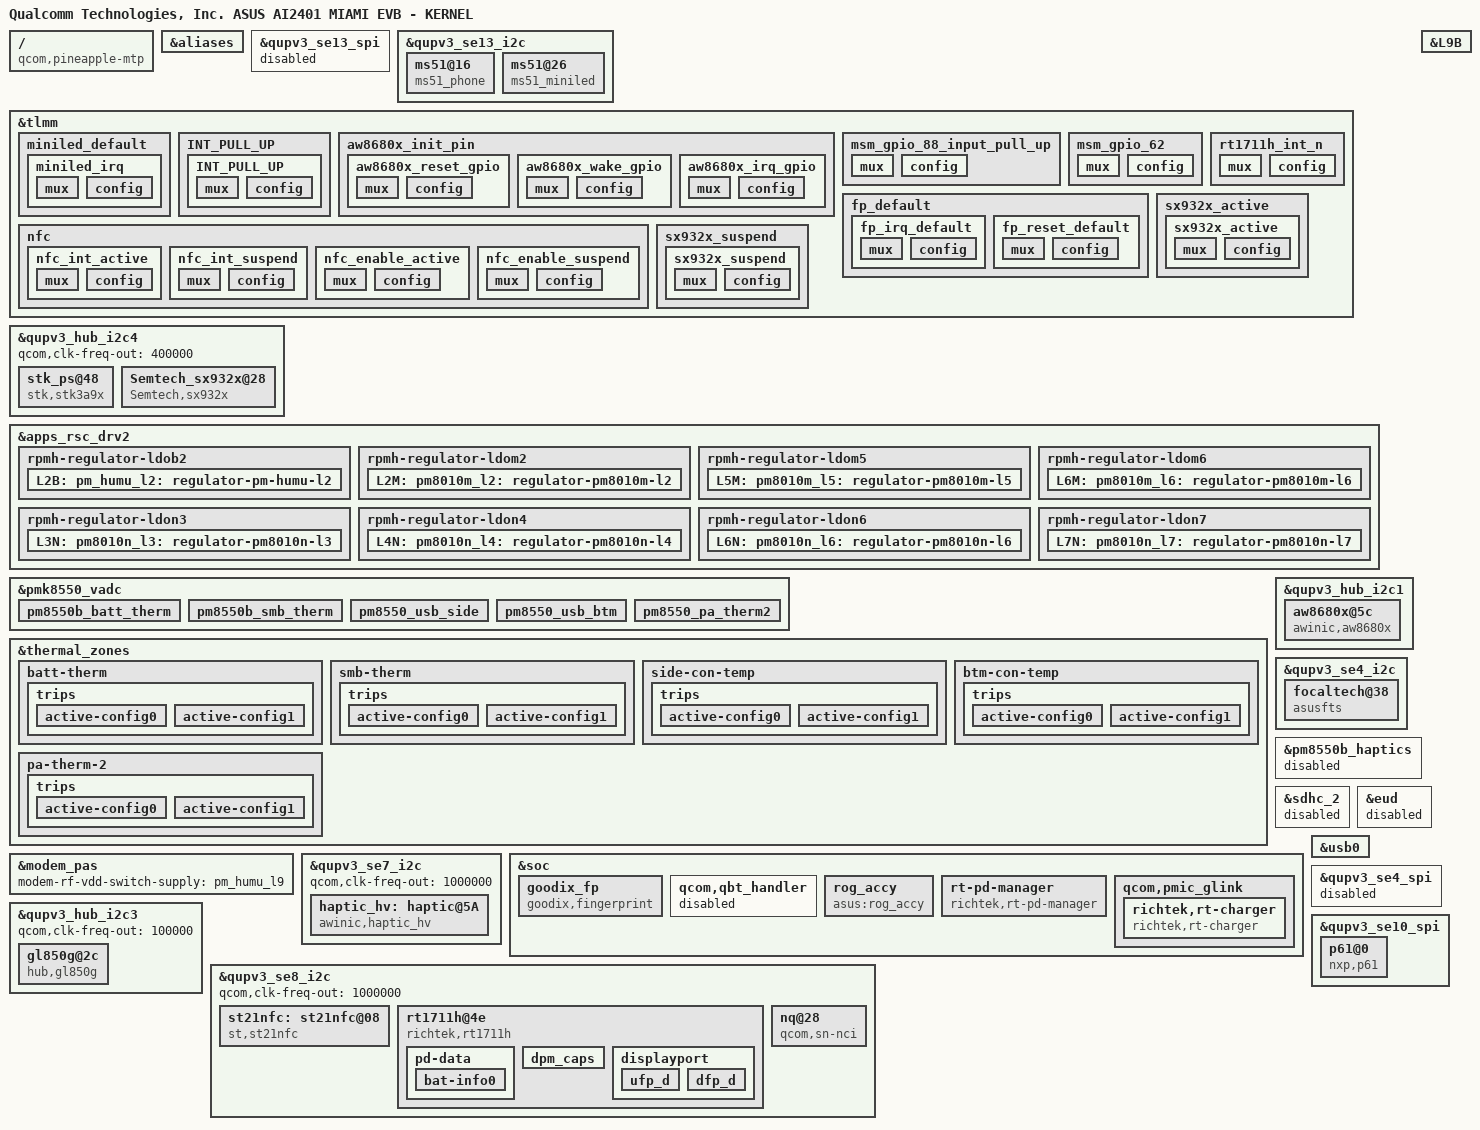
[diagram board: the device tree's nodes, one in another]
/dts-v1/;
/plugin/;

#include "pineapple-mtp.dtsi"

/ {
	model = "Qualcomm Technologies, Inc. ASUS AI2401 MIAMI EVB - KERNEL";
	compatible = "qcom,pineapple-mtp", "qcom,pineapple", "qcom,pineapplep-mtp", "qcom,pineapplep", "qcom,mtp";
	qcom,msm-id = <557 0x10000>, <557 0x20000>, <577 0x10000>, <577 0x20000>;
	qcom,board-id = <30 0>;
};

&aliases {
		i2c4 = "/soc/qcom,qupv3_2_geni_se@8c0000/i2c@880000";
		i2c5 = "/soc/qcom,qupv3_2_geni_se@8c0000/i2c@894000";
		i2c6 = "/soc/qcom,qupv3_i2c_geni_se@9c0000/i2c@984000";
		i2c7 = "/soc/qcom,qupv3_i2c_geni_se@9c0000/i2c@98c000";
		i2c8 = "/soc/qcom,qupv3_i2c_geni_se@9c0000/i2c@990000";
		i2c9 = "/soc/qcom,qupv3_1_geni_se@ac0000/i2c@a8c000";
		i2c10 = "/soc/qcom,qupv3_1_geni_se@ac0000/i2c@a98000";
		i2c11 = "/soc/qcom,qupv3_1_geni_se@ac0000/i2c@a9c000";
		i2c12 = "/soc/qcom,qupv3_2_geni_se@8c0000/i2c@884000";
		spi0 = "/soc/qcom,qupv3_1_geni_se@ac0000/spi@a90000";
		spi1 = "/soc/qcom,qupv3_2_geni_se@8c0000/spi@888000";
		spi2 = "/soc/qcom,qupv3_2_geni_se@8c0000/spi@88c000";
};

/*   ====================================
*    overlay for aura - start
*    ====================================
*/

&qupv3_se13_spi {
    status = "disable";
};

&qupv3_se13_i2c {
    status = "ok";
    ms51@16 {
        compatible = "ms51_phone";
        reg = <0x16>;

        nuvoton,logo_5p0_en = <&pm8550b_gpios 9 0x0>;
        nuvoton,wakeup_pin = <&tlmm 183 0>;
        nuvoton,hw_stage = <5>;
    };
    ms51@26 {
        compatible = "ms51_miniled";
        reg = <0x26>;

        nuvoton,logo_5p0_en = <&pm8550b_gpios 9 0x0>;
        nuvoton,wakeup_pin = <&tlmm 183 0>;

        miniled,irq-gpio = <&tlmm 15 0>;
        pinctrl-names = "miniled_default";
        pinctrl-0 = <&miniled_irq>;
    };
};

&tlmm {
	miniled_default {
		miniled_irq: miniled_irq {
			    mux {
					pins = "gpio15";
					function = "gpio";
			    };
			    config {
					pins = "gpio15";
					drive-strength = <6>;
					bias-pull-up;
					input-enable;
			    };
		};
	};
};

/*   ====================================
*    overlay for aura - end
*    ====================================
*/

/*   ====================================
*    overlay for ALS/PS - start
*    ====================================
*/
&qupv3_hub_i2c4 {
        status = "ok";
	qcom,clk-freq-out = <400000>;
        /*
        stk_ps@48 {
            compatible = "stk,stk3a9x";
            reg = <0x48>;
            clocks = <&clock_gcc clk_ln_bb_clk3_pin>;
            clock-names = "ref_clk";                
            stk,irq-gpio = <&tlmm 16 IRQ_TYPE_EDGE_FALLING>;
            stk,als_scale = <1000>;
            //stk,als_is_dri;
            stk,ps_thd_h = <1000>;
            stk,ps_thd_l = <900>;
            stk,ps_ctir = <0>;
            stk,ps_is_dri;
        };
        */
        
        stk_ps@48 {
               compatible = "stk,stk3a9x";
               reg = <0x48>;
               stk,irq-gpio = <&tlmm 64 0x0>;
               vcc_psensor-supply = <&L2B>;
               vcc_psensor_1v8-supply  = <&L1B>;
		       pinctrl-names = "INT_PULL_UP", "FT_INT_suspend", "snt_id_active", "snt_id_suspend";
		       pinctrl-0 = <&INT_PULL_UP>;
        };
};

&tlmm {
	INT_PULL_UP {
		INT_PULL_UP: INT_PULL_UP {
			mux {
				pins = "gpio64";
				function = "gpio";
			};
			config {
				pins = "gpio64";
				bias-pull-up;
				drive-strength = <2>;
			};
		};
	};
};

&apps_rsc_drv2 {
	rpmh-regulator-ldob2 {
		L2B: pm_humu_l2: regulator-pm-humu-l2 {
			regulator-min-microvolt = <3008000>;
			regulator-max-microvolt = <3350000>;
			qcom,init-voltage = <3300000>;
		};
	};

	rpmh-regulator-ldom2 {
		L2M: pm8010m_l2: regulator-pm8010m-l2 {
			regulator-min-microvolt = <1240000>;
			regulator-max-microvolt = <1240000>;
			qcom,init-voltage = <1240000>;
		};
	};

	rpmh-regulator-ldom5 {
		L5M: pm8010m_l5: regulator-pm8010m-l5 {
			regulator-min-microvolt = <2800000>;
			regulator-max-microvolt = <2800000>;
			qcom,init-voltage = <2800000>;
		};
	};

	rpmh-regulator-ldom6 {
		L6M: pm8010m_l6: regulator-pm8010m-l6 {
			regulator-min-microvolt = <1800000>;
			regulator-max-microvolt = <1800000>;
			qcom,init-voltage = <1800000>;
		};
	};

	rpmh-regulator-ldon3 {
		L3N: pm8010n_l3: regulator-pm8010n-l3 {
			regulator-min-microvolt = <2800000>;
			regulator-max-microvolt = <2800000>;
			qcom,init-voltage = <2800000>;
		};
	};

	rpmh-regulator-ldon4 {
		L4N: pm8010n_l4: regulator-pm8010n-l4 {
			regulator-min-microvolt = <2800000>;
			regulator-max-microvolt = <2800000>;
			qcom,init-voltage = <2800000>;
		};
	};

	rpmh-regulator-ldon6 {
		L6N: pm8010n_l6: regulator-pm8010n-l6 {
			regulator-min-microvolt = <1800000>;
			regulator-max-microvolt = <1800000>;
			qcom,init-voltage = <1800000>;
		};
	};

	rpmh-regulator-ldon7 {
		L7N: pm8010n_l7: regulator-pm8010n-l7 {
			regulator-min-microvolt = <2800000>;
			regulator-max-microvolt = <2800000>;
			qcom,init-voltage = <2800000>;
		};
	};
};

/*   ====================================
*    overlay for ALS/PS - end
*    ====================================
*/

/*   ====================================
*    overlay for thermal - start
*    ====================================
*/

&pmk8550_vadc {
	pm8550b_batt_therm {
		reg = <PM8550B_ADC5_GEN3_AMUX_THM1_BATT_THERM_100K_PU>;
		label = "pm8550b_batt_therm";
		qcom,ratiometric;
		qcom,hw-settle-time = <200>;
		qcom,pre-scaling = <1 1>;
		qcom,adc-tm-type = <1>;
	};

	pm8550b_smb_therm {
		reg = <PM8550B_ADC5_GEN3_AMUX_THM3_SMB_TEMP_V_100K_PU>;
		label = "pm8550b_smb_therm";
		qcom,ratiometric;
		qcom,hw-settle-time = <200>;
		qcom,pre-scaling = <1 1>;
		qcom,adc-tm-type = <1>;
	};

//ASUS_BSP : Add for charger +++
	pm8550_usb_side {
		reg = <PM8550_ADC5_GEN3_AMUX_THM6_GPIO2_100K_PU>;
		label = "pm8550_usb_side";
		qcom,ratiometric;
		qcom,hw-settle-time = <200>;
		qcom,pre-scaling = <1 1>;
		qcom,adc-tm-type = <1>;
	};

	pm8550_usb_btm {
		reg = <PM8550_ADC5_GEN3_AMUX2_GPIO4_100K_PU>;
		label = "pm8550_usb_btm";
		qcom,ratiometric;
		qcom,hw-settle-time = <200>;
		qcom,pre-scaling = <1 1>;
		qcom,adc-tm-type = <1>;
	};	
//ASUS_BSP : Add for charger ---

	pm8550_pa_therm2{
		reg = <PM8550_ADC5_GEN3_AMUX1_GPIO3_100K_PU>;
		label = "pm8550_pa_therm_2";
		qcom,ratiometric;
		qcom,hw-settle-time = <200>;
		qcom,pre-scaling = <1 1>;
		qcom,adc-tm-type = <1>;
	};
};

&thermal_zones {
	batt-therm {
		polling-delay-passive = <0>;
		polling-delay = <0>;
		thermal-sensors = <&pmk8550_vadc PM8550B_ADC5_GEN3_AMUX_THM1_BATT_THERM_100K_PU>;
		trips {
			active-config0 {
				temperature = <125000>;
				hysteresis = <1000>;
				type = "passive";
			};

			active-config1 {
				temperature = <125000>;
				hysteresis = <1000>;
				type = "passive";
			};
		};
	};

	smb-therm {
		polling-delay-passive = <0>;
		polling-delay = <0>;
		thermal-sensors = <&pmk8550_vadc PM8550B_ADC5_GEN3_AMUX_THM3_SMB_TEMP_V_100K_PU>;
		trips {
			active-config0 {
				temperature = <125000>;
				hysteresis = <1000>;
				type = "passive";
			};

			active-config1 {
				temperature = <125000>;
				hysteresis = <1000>;
				type = "passive";
			};
		};
	};

//ASUS_BSP : Add for charger +++	
	side-con-temp {
		polling-delay-passive = <0>;
		polling-delay = <0>;
		thermal-sensors = <&pmk8550_vadc PM8550_ADC5_GEN3_AMUX_THM6_GPIO2_100K_PU>;
		trips {
			active-config0 {
				temperature = <125000>;
				hysteresis = <1000>;
				type = "passive";
			};

			active-config1 {
				temperature = <125000>;
				hysteresis = <1000>;
				type = "passive";
			};
		};
	};

	btm-con-temp {
		polling-delay-passive = <0>;
		polling-delay = <0>;
		thermal-sensors = <&pmk8550_vadc PM8550_ADC5_GEN3_AMUX2_GPIO4_100K_PU>;
		trips {
			active-config0 {
				temperature = <125000>;
				hysteresis = <1000>;
				type = "passive";
			};
			active-config1 {
				temperature = <125000>;
				hysteresis = <1000>;
				type = "passive";
			};
		};
	};	
//ASUS_BSP : Add for charger ---

	pa-therm-2 {
		polling-delay-passive = <0>;
		polling-delay = <0>;
		thermal-sensors = <&pmk8550_vadc PM8550_ADC5_GEN3_AMUX1_GPIO3_100K_PU>;
		trips {
			active-config0 {
				temperature = <125000>;
				hysteresis = <1000>;
				type = "passive";
			};

			active-config1 {
				temperature = <125000>;
				hysteresis = <1000>;
				type = "passive";
			};
		};
	};
};

/*   ====================================
*    overlay for thermal - end
*    ====================================
*/

/*   ====================================
*    overlay for Grip - start
*    ====================================
*/

&qupv3_hub_i2c1 {	
	/* AWINIC AW8680X */
	status = "ok";
	aw8680x@5c {
		compatible = "awinic,aw8680x";
		reg = <0x5c>;
		//report-mode;
		irq-gpio = <&tlmm 90 0>;
		reset-gpio = <&tlmm 126 0>;
		//state-gpio = <&tlmm 186 0>;
		wake-gpio = <&tlmm 127 0>;
		id-gpio = <&pm8550vs_c_gpios 5 0x0>; //PM8550VS_C_GPIO_05
		
		pinctrl-names = "aw8680x_reset_gpio", "aw8680x_irq_gpio", "aw8680x_wake_gpio";
		pinctrl-0 = <&aw8680x_reset_gpio>;
		pinctrl-1 = <&aw8680x_irq_gpio>;
		pinctrl-2 = <&aw8680x_wake_gpio>;		
	};
};

&tlmm {
	aw8680x_init_pin {
		aw8680x_reset_gpio: aw8680x_reset_gpio {
			mux {
				pins = "gpio126";
				function = "gpio";
			};
			config {
				pins = "gpio126";
				drive-strength = <4>;
				bias-pull-up;
				output-high;				
			};
		};
		
		aw8680x_wake_gpio: aw8680x_wake_gpio {
			mux {
				pins = "gpio127";
				function = "gpio";
			};
			config {
				pins = "gpio127";
				drive-strength = <4>;
				bias-pull-up;
				output-high;		
			};
		};			


		aw8680x_irq_gpio: aw8680x_irq_gpio {
			mux {
				pins = "gpio90";
				function = "gpio";
			};
			config {
				pins = "gpio90";
				bias-pull-up;
				drive-strength = <2>;
				input-enable;
			};
		};	
	};		
};

/*   ====================================
*    overlay for Grip - end
*    ====================================
*/

&qupv3_se4_i2c {
	#address-cells = <1>;
	#size-cells = <0>;
	status = "ok";
	qcom,i2c-touch-active = "asusfts";
	qcom,touch-active = "asusfts";
	qcom,la-vm;
	qcom,shared;

	focaltech@38 {
		compatible = "asusfts";
		reg = <0x38>;
		focaltech,reset-gpio = <&tlmm 161 0x00>;
		focaltech,irq-gpio = <&tlmm 162 0x2008>;
		focaltech,max-touch-number = <10>;
		focaltech,display-coords = <0 0 1080 2448>;
		focaltech,touch-type = "primary";

		vdd-supply = <&L14B>;
		vcc_i2c-supply = <&L14B>; //should be L4B

		pinctrl-names = "pmx_ts_active", "pmx_ts_suspend","pmx_ts_release";
		pinctrl-0 = <&ts_active>;
		pinctrl-1 = <&ts_int_suspend &ts_reset_suspend>;
		pinctrl-2 = <&ts_release>;
		//panel = <&dsi_ams667uu07_fhd_plus_dsc_cmd &dsi_ams678_fhd_plus_dsc_cmd &dsi_ams678_er2_fhd_plus_dsc_cmd>
	};
};

// ASUS_BSP+++ Phone Antenna

&L9B {
	regulator-min-microvolt = <2800000>;
	regulator-max-microvolt = <2800000>;
	qcom,init-voltage = <2800000>;
};

&modem_pas {
	modem-rf-vdd-switch-supply = <&pm_humu_l9>;
};
// ASUS_BSP--- Phone Antenna

//ASUS_BSP: aw haptic +++

&pm8550b_haptics {
	status = "disabled";
};

&qupv3_se7_i2c {
	status = "ok";
	qcom,clk-freq-out = <1000000>;
	#address-cells = <1>;
	#size-cells = <0>;

	haptic_hv: haptic@5A {
		compatible = "awinic,haptic_hv";
		reg = <0x5A>;
		irq-gpio = <&tlmm 88 0>;
		reset-gpio = <&tlmm 58 0>;
		pinctrl-names = "irq_active";
		pinctrl-0 = <&msm_gpio_88_input_pull_up &msm_gpio_62>;
		f0_pre = < 1300 >;
		mode = /bits/ 8 < 5 >;
		f0_cali_percent = /bits/ 8 < 15 >;

/*******************************aw869x*******************************/
		aw869x_max_bst_vol = /bits/ 8 <0x1f>;
		aw869x_cont_drv_lev = /bits/ 8 < 105 >;
		aw869x_cont_drv_lvl_ov = /bits/ 8 < 125 >;
		aw869x_cont_td = < 0x009A >;
		aw869x_cont_zc_thr = < 0x0FF1 >;
		aw869x_cont_num_brk = /bits/ 8 < 3 >;
		aw869x_f0_coeff = < 260 >; /*Don't modify it 2.604167*/
		aw869x_duration_time = /bits/ 8 < 20 30 60 >;
		aw869x_f0_trace_parameter = /bits/ 8 < 0x05 0x03 0x02 0x0f >;
		aw869x_bemf_config = /bits/ 8 < 0x10 0x08 0x03 0xf8 >;
		aw869x_tset = /bits/ 8 < 0x12 >;
		aw869x_r_spare = /bits/ 8 < 0x68 >;
		aw869x_bstdbg = /bits/ 8 < 0x30 0xeb 0xd4 0 0 0 >;
		aw869x_trig_config = /bits/ 8 < 0 1 1 1 2 0 1 1 1 2 0 1 1 1 2 >;
		aw869x_bst_vol_default = < 8000 >;

/******************************aw869xx*******************************/
		aw869xx_gain_bypass = /bits/ 8 < 1 >;
		aw869xx_max_bst_vol = /bits/ 8 <0x3f>;
		aw869xx_brk_bst_md = /bits/ 8 < 0 >;
		aw869xx_cont_drv1_lvl = /bits/ 8 < 0x7F >;
		aw869xx_cont_drv2_lvl = /bits/ 8 < 0x36 >;
		aw869xx_cont_brk_time = /bits/ 8 < 0x08 >;
		aw869xx_cont_tset = /bits/ 8 < 0x06 >;
		aw869xx_cont_bemf_set = /bits/ 8 < 0x02 >;
		aw869xx_cont_drv_width = /bits/ 8 < 0x6A >;
		aw869xx_cont_track_margin = /bits/ 8 < 0x12 >;
		aw869xx_cont_brk_gain = /bits/ 8 < 0x08 >;
		aw869xx_cont_bst_brk_gain = /bits/ 8 < 0x05 >;
		aw869xx_cont_wait_num = /bits/ 8 < 0x06 >;
		aw869xx_cont_drv1_time = /bits/ 8 < 0x04 >;
		aw869xx_cont_drv2_time = /bits/ 8 < 0x14 >;
		aw869xx_duration_time = /bits/ 8 < 20 30 60 >;
		aw869xx_sine_array = /bits/ 8 < 0x05 0xB2 0xFF 0xEF >;
		aw869xx_d2s_gain = /bits/ 8 < 0x04 >;
		aw869xx_bstcfg = /bits/ 8 < 0x20 0x24 0x96 0x40 0x11 >;
		aw869xx_trig_config = /bits/ 8 < 0 0 0 1 0 2 0 0
						 0 0 0 1 0 2 0 0
						 0 0 0 1 0 2 0 0 >;
		aw869xx_bst_vol_default = < 8500 >;
		/* aw869xx_is_enabled_auto_bst; */
		/* aw869xx_is_enabled_i2s; */
		/* aw869xx_is_enabled_one_wire; */

/******************************aw8671x*******************************/
		aw8671x_gain_bypass = /bits/ 8 < 1 >;
		aw8671x_brk_bst_md = /bits/ 8 < 0 >;
		aw8671x_cont_drv1_lvl = /bits/ 8 < 0x7F >;
		aw8671x_cont_drv2_lvl = /bits/ 8 < 0x36 >;
		aw8671x_cont_brk_time = /bits/ 8 < 0x08 >;
		aw8671x_cont_tset = /bits/ 8 < 0x06 >;
		aw8671x_cont_bemf_set = /bits/ 8 < 0x02 >;
		aw8671x_cont_drv_width = /bits/ 8 < 0x6A >;
		aw8671x_cont_track_margin = /bits/ 8 < 0x12 >;
		aw8671x_cont_brk_gain = /bits/ 8 < 0x08 >;
		aw8671x_cont_bst_brk_gain = /bits/ 8 < 0x05 >;
		aw8671x_cont_wait_num = /bits/ 8 < 0x06 >;
		aw8671x_cont_drv1_time = /bits/ 8 < 0x04 >;
		aw8671x_cont_drv2_time = /bits/ 8 < 0x14 >;
		aw8671x_duration_time = /bits/ 8 < 20 30 60 >;
		aw8671x_d2s_gain = /bits/ 8 < 0x04 >;
		aw8671x_trig_config = /bits/ 8 < 0 0 0 1 0 2 0 0
						 0 0 0 1 0 2 0 0
						 0 0 0 1 0 2 0 0 >;
		aw8671x_bst_vol_default = < 6336 >;
		/* aw8671x_is_enabled_auto_bst; */
		/* aw8671x_is_enabled_i2s; */
		/* aw8671x_is_enabled_one_wire; */

/******************************aw8692x*******************************/
		aw8692x_gain_bypass = /bits/ 8 < 1 >;
		aw8692x_cont_drv1_lvl = /bits/ 8 < 0x7F >;
		aw8692x_cont_drv2_lvl = /bits/ 8 < 0x50 >;
		aw8692x_cont_drv1_time = /bits/ 8 < 0x04 >;
		aw8692x_cont_drv2_time = /bits/ 8 < 0x06 >;
		aw8692x_cont_drv_width = /bits/ 8 < 0x9C >;
		aw8692x_cont_track_margin = /bits/ 8 < 0x0C >;
		aw8692x_cont_brk_gain = /bits/ 8 < 0x08 >;
		aw8692x_cont_bst_brk_gain = /bits/ 8 < 0x05 >;
		aw8692x_cont_wait_num = /bits/ 8 < 0x06 >;
		aw8692x_cont_brk_time = /bits/ 8 < 0x08 >;
		aw8692x_brk_bst_md = /bits/ 8 < 0 >;
		aw8692x_cont_tset = /bits/ 8 < 0x06 >;
		aw8692x_cont_bemf_set = /bits/ 8 < 0x02 >;
		aw8692x_duration_time = /bits/ 8 < 20 30 60 >;
		aw8692x_d2s_gain = /bits/ 8 < 0x04 >;
		aw8692x_trig_config = /bits/ 8 < 0 0 1 3 0 2 0 1
						 0 0 1 4 0 2 0 1
						 0 0 0 1 0 2 0 0 >;
		aw8692x_bst_vol_default = < 8000 >;
		/* aw8692x_is_enabled_auto_bst; */
		/* aw8692x_is_enabled_one_wire; */
	};
};

&tlmm {
	/* GPIO_88 : INTERRUPT_N */
	msm_gpio_88_input_pull_up: msm_gpio_88_input_pull_up {
		mux {
			 pins = "gpio88";
			 function = "gpio";
		};
		config {
			pins = "gpio88";
			drive-strength = <2>;
			bias-pull-up;
			input-enable;
		};
	};
	/* GPIO_62 : trig */
	msm_gpio_62: msm_gpio_62 {
		mux {
			 pins = "gpio62";
			 function = "gpio";
		};
		config {
			pins = "gpio62";
			drive-strength = <2>;
			bias-pull-down;
			output-low;
		};
	};
};

//ASUS_BSP: aw haptic ---

&sdhc_2 {
	status = "disabled";
};

/*
//Hall_sensor +++	
//use gpio87 and gpio200 for interrupt pin
&soc {	
	hall1_sensor {	
		compatible = "qcom,hall";	
		pinctrl-names = "hall1_gpio_high","hall1_gpio_low";	
		pinctrl-0 = <&gpio_hall1_active>;	
		pinctrl-1 = <&gpio_hall1_suspend>;	
		qcom,hall1-gpio = <&tlmm 87 0x0>;	
	};
	hall2_sensor {	
		compatible = "qcom,hall_2nd";	
		pinctrl-names = "hall2_gpio_high","hall2_gpio_low";		
		pinctrl-0 = <&gpio_hall2_active>;	
		pinctrl-1 = <&gpio_hall2_suspend>;	
		qcom,hall2-gpio = <&tlmm 200 0x0>;	
	};
};	

&tlmm{
	hall_int_pin {		
		gpio_hall1_active: gpio_hall1_active {	
			mux {	
				pins = "gpio87";	
				function = "gpio";	
			};

			config {	
				pins = "gpio87";	
				drive-strength = <2>;	
				bias-pull-up;	
				input-enable;
			};	
		};

		gpio_hall1_suspend: gpio_hall1_suspend {	
			mux {	
				pins = "gpio87";	
				function = "gpio";	
			};	

			config {	
				pins = "gpio87";	
				drive-strength = <2>;	
				bias-pull-down;
				input-enable;	
			};	
		};	

		gpio_hall2_active: gpio_hall2_active {	
			mux {	
				pins = "gpio200";	
				function = "gpio";	
			};

			config {	
				pins = "gpio200";	
				drive-strength = <2>;	
				bias-pull-up;	
				input-enable;
			};	
		};

		gpio_hall2_suspend: gpio_hall2_suspend {	
			mux {	
				pins = "gpio200";	
				function = "gpio";	
			};	

			config {	
				pins = "gpio200";	
				drive-strength = <2>;	
				bias-pull-down;
				input-enable;	
			};	
		};	
	};	
};
//Hall_sensor ---
*/
//ASUS BSP Fingerprint +++
&soc {
	goodix_fp {
		compatible = "goodix,fingerprint";
		fp-gpio-irq = <&tlmm 92 0x00>;
		fp-gpio-reset = <&tlmm 89 0x0>;
		fp-gpio-cs = <&tlmm 43 0x0>;
		vcc-supply = <&L7N>;
		asus-fp,vcc-voltage=<3150000 3300000>;
		pinctrl-names = "fp_default";
		pinctrl-0 = <&fp_irq_default &fp_reset_default>;
		status = "okay";
 	};

	//Disable qcom default FP setting
	qcom,qbt_handler {
		status = "disable";
	};
};

&tlmm{
	fp_default {
		fp_irq_default: fp_irq_default {
			mux {
				pins = "gpio92";
				function = "gpio";
			};
			config {
				pins = "gpio92";
				bias-disable;
				drive-strength = <8>;
			};
		};

		fp_reset_default: fp_reset_default {
			mux {
				pins = "gpio89";
				function = "gpio";
			};
			config {
				pins = "gpio89";
				bias-pull-down;
				drive-strength = <8>;
			};
		};
	};
};
//ASUS BSP Fingerprint ---

//ASUS BSP ACCY +++
&soc {
	rog_accy {
		compatible = "asus:rog_accy";
		status = "okay";

		accy,vph_ctrl = <&tlmm 111 0x0>;
		accy,type = "primary";
	};
};
//ASUS BSP ACCY ---

//ASUS USB
&eud {
	status = "disabled";
};

//ASUS_BSP : usb g1850 hub
&qupv3_hub_i2c3 {
	status = "ok";
	qcom,clk-freq-out = <100000>;
	gl850g@2c {
		compatible = "hub,gl850g";
		reg = <0x2c>;

		HUB_RESET = <&tlmm 106 0x0>;
		LDO_ENABLE = <&pm8550vs_c_gpios 4 0x0>; //PM8550VS_C_GPIO_04
	};
};

//ASUS_BSP : usb mux
&usb0 {
	MUX1_OE = <&tlmm 28 0x0>;
	MUX2_OE = <&tlmm 120 0x0>;
	MUX2_SEL = <&tlmm 121 0x0>;
	MUX3_OE = <&tlmm 93 0x0>;
	MUX3_SEL = <&tlmm 91 0x0>;
};

//ASUS BSP Richtek TypeC PD +++
&qupv3_se8_i2c {
	status = "ok";
	qcom,clk-freq-out = <1000000>;

	st21nfc: st21nfc@08 {
		compatible = "st,st21nfc";
		reg = <0x08>;
		irq-gpios = <&tlmm 201 0x00>;
		reset-gpios = <&tlmm 189 0x00>;
		clkreq-gpios = <&tlmm 198 0x00>;
		interrupt-parent = <&tlmm>;
		interrupts = <201 0>;
		interrupt-names = "nfc_irq";
		pinctrl-names = "nfc_active", "nfc_suspend";
		pinctrl-0 = <&nfc_int_active &nfc_enable_active>;
		pinctrl-1 = <&nfc_int_suspend &nfc_enable_suspend>;
	};

	rt1711h@4e {
		compatible = "richtek,rt1711h";
		reg = <0x4e>;
		status = "ok";
		tcpc-dual,supported_modes = <0>; /* 0: dfp/ufp, */
						 /* 1: dfp, 2: ufp */
		rt-tcpc,name = "typec"; /* tcpc_device's name */
		rt-tcpc,role_def = <5>; /* 0: Unknown, 1: SNK, 2: SRC */
					/* 3: DRP, 4: Try.SRC, 5: Try.SNK */
		rt-tcpc,rp_level = <0>; /* 0: Default, 1: 1.5, 2: 3.0 */
		rt-tcpc,vconn_supply = <0>;  /* 0: Never, 1: Always, */
					     /* 2: EMarkOnly, 3: StartOnly */
		rt1711pd,intr_gpio = <&tlmm 137 0x0>;
		rt1711pd,intr_gpio_num = <137>;
		pinctrl-names = "rt1711h_int_n";
		pinctrl-0 = <&rt1711h_int_n>;
		pd-data {
			pd,vid = <0x29cf>;
			pd,pid = <0x1711>;
			pd,source-cap-ext = /bits/ 8 <0xcf 0x29 0x11 0x17
						      0x00 0x00 0x00 0x00
						      0x00 0x00 0x00 0x00
						      0x00 0x00 0x00 0x00
						      0x00 0x00 0x00 0x00
						      0x00 0x00 0x01 0x02
						      0x00>;
			pd,sink-cap-ext = /bits/ 8 <0xcf 0x29 0x11 0x17
						    0x00 0x00 0x00 0x00
						    0x00 0x00 0x01 0x00
						    0x00 0x00 0x00 0x00
						    0x01 0x0b 0x01 0x0a
						    0x0a 0x00 0x00 0x00>;
			pd,mfrs = "RichtekTCPC";

			/*
			 *	VSAFE5V = 0, MAX_POWER = 1, CUSTOM = 2,
			 *	MAX_POWER_LV = 0x21, MAX_POWER_LVIC = 0x31
			 *	MAX_POWER_HV = 0x41, MAX_POWER_HVIC = 0x51
			 */
			pd,charging_policy = <0x31>;

			/*
			 * Fixed 5V, 500 mA <0x00019032>
			 * Fixed 5V, 1A <0x00019064>
			 * Fixed 5V, 2A <0x000190c8>
			 * Fixed 5V, 3A <0x0001912c>
			 * Fixed 9V, 500 mA <0x0002d032>
			 * Fixed 9V, 1A <0x0002d064>
			 * Fixed 9V, 2A <0x0002d0c8>
			 * Fixed 9V, 3A <0x0002d12c>
			 * Variable 5-9V, 1A <0x8642d064>
			 * Variable 5-9V, 2A <0x8642d0c8>
			 * Variable 5-9V, 3A <0x8642d12c>
			 */
			pd,source-pdo-size = <1>;
			pd,source-pdo-data = <0x00019032>;
			pd,sink-pdo-size = <1>;
			pd,sink-pdo-data = <0x000190c8>;

			/*
			 * No DP, host + device
			 *	pd,id-vdo-size = <6>;
			 *	pd,id-vdo-data = <0xd14029cf 0x0 0x17110000
						  0x61000000 0x0 0x41000000>;
			 * With DP
			 *	pd,id-vdo-size = <6>;
			 *	pd,id-vdo-data = <0xd54029cf 0x0 0x17110000
						  0x61000000 0x0 0x41000000>;
			 */

			pd,id-vdo-size = <6>;
			pd,id-vdo-data = <0xd14029cf 0x0 0x17110000
					  0x61000000 0x0 0x41000000>;

			bat,nr = <1>;
			pd,country_nr = <0>;

			bat-info0 {
				bat,vid = <0x29cf>;
				bat,pid = <0x1711>;
				bat,mfrs = "bat1";
				bat,design_cap = <3000>;
			};

			//bat-info1 {
			//	bat,vid = <0x8abc>;
			//	bat,pid = <0x5234>;
			//	bat,mfrs = "bat2";
			//	bat,design_cap = <4000>;
			//};

			//country0 {
			//	pd,country_code = <0x5457>;
			//	pd,country_len = <2>; /* max len = 26 */
			//	pd,country_data = <0xff 0xff>;
			//};

			//country1 {
			//	pd,country_code = <0x5553>;
			//	pd,country_len = <3>; /* max len = 26 */
			//	pd,country_data = <0xf1 0xf2 0xf3>;
			//};
		};
		dpm_caps {
			local_dr_power;
			local_dr_data;
			//local_ext_power;
			local_usb_comm;
			//local_usb_suspend;
			//local_high_cap;
			//local_give_back;
			local_no_suspend;
			//local_vconn_supply;

			//attempt_discover_cable_dfp;
			attempt_enter_dp_mode;
			attempt_discover_cable;
			attempt_discover_id;
			attempt_discover_svid;

			/* 0: disable, 1: prefer_snk, 2: prefer_src */
			pr_check = <0>;
			//pr_reject_as_source;
			//pr_reject_as_sink;
			//pr_check_gp_source;
			//pr_check_gp_sink;

			/* 0: disable, 1: prefer_ufp, 2: prefer_dfp */
			dr_check = <0>;
			//dr_reject_as_dfp;
			//dr_reject_as_ufp;
		};
		displayport {
			/* connection type = "both", "ufp_d", "dfp_d" */
			1st_connection = "dfp_d";
			2nd_connection = "dfp_d";
			signal,dp_v13;
			//signal,dp_gen2;
			//usbr20_not_used;
			typec,receptacle;
			ufp_d {
				//pin_assignment,mode_c;
				//pin_assignment,mode_d;
				//pin_assignment,mode_e;
			};
			dfp_d {
				pin_assignment,mode_c;
				pin_assignment,mode_d;
				pin_assignment,mode_e;
			};
		};
	};

	// ASUS_BSP NFC +++
	nq@28 {
		compatible = "qcom,sn-nci";
		reg = <0x29>;
		qcom,sn-irq = <&tlmm 201 0x00>;
		qcom,sn-ven = <&tlmm 189 0x00>;
		qcom,sn-clkreq = <&tlmm 198 0x00>;
		qcom,sn-szone = "enable";
		#qcom,sn-vdd-1p8-supply = <&L3C>;
		#qcom,sn-vdd-1p8-voltage = <1200000 1200000>;
		#qcom,sn-vdd-1p8-current = <157000>;
		interrupt-parent = <&tlmm>;
		interrupts = <201 0>;
		interrupt-names = "nfc_irq";
		pinctrl-names = "nfc_active", "nfc_suspend";
		pinctrl-0 = <&nfc_int_active &nfc_enable_active>;
		pinctrl-1 = <&nfc_int_suspend &nfc_enable_suspend>;
	};
	// ASUS_BSP NFC ---
};

&soc {
	rt-pd-manager {
		compatible = "richtek,rt-pd-manager";
	};

	qcom,pmic_glink {
		richtek,rt-charger {
			compatible = "richtek,rt-charger";
			//vconn-supply = <&vconn_5v>;
		};
	};
};

&tlmm {
	rt1711h_int_n: rt1711h_int_n {
		mux {
			pins = "gpio137";
			function = "gpio";
		};

		config {
			pins = "gpio137";
			drive-strength = <2>;
			bias-pull-up;
		};
	};
};
//ASUS BSP Richtek TypeC PD ---

&qupv3_se4_spi {
	status = "disabled";
};
&qupv3_se4_i2c {
	#address-cells = <1>;
	#size-cells = <0>;
	status = "ok";
	qcom,i2c-touch-active = "asusfts";
	qcom,touch-active = "asusfts";
	qcom,la-vm;
	qcom,shared;

	focaltech@38 {
		compatible = "asusfts";
		reg = <0x38>;
		focaltech,reset-gpio = <&tlmm 161 0x00>;
		focaltech,irq-gpio = <&tlmm 162 0x2008>;
		focaltech,max-touch-number = <10>;
		focaltech,display-coords = <0 0 1080 2448>;
		focaltech,touch-type = "primary";

		vdd-supply = <&L14B>;
		vcc_i2c-supply = <&L14B>; //should be L4B

		pinctrl-names = "pmx_ts_active", "pmx_ts_suspend","pmx_ts_release";
		pinctrl-0 = <&ts_active>;
		pinctrl-1 = <&ts_int_suspend &ts_reset_suspend>;
		pinctrl-2 = <&ts_release>;
		//panel = <&dsi_ams667uu07_fhd_plus_dsc_cmd &dsi_ams678_fhd_plus_dsc_cmd &dsi_ams678_er2_fhd_plus_dsc_cmd>
	};
};

// ASUS_BSP NFC +++
&qupv3_se10_spi {
	status = "ok";
	p61@0 {
		compatible = "nxp,p61";
		reg = <0x0>;
		spi-max-frequency = <20000000>;
		nxp,nfcc = "4-0029";
	};
};

&tlmm {
	nfc {
		nfc_int_active: nfc_int_active {
			/* active state */
			mux {
				/* NFC Read Interrupt */
				pins = "gpio201";
				function = "gpio";
			};

			config {
				pins = "gpio201";
				drive-strength = <2>; /* 2 MA */
				bias-pull-down;
			};
		};

		nfc_int_suspend: nfc_int_suspend {
			/* sleep state */
			mux {
				/* NFC Read Interrupt */
				pins = "gpio201";
				function = "gpio";
			};

			config {
				pins = "gpio201";
				drive-strength = <2>; /* 2 MA */
				bias-pull-down;
			};
		};

		nfc_enable_active: nfc_enable_active {
			mux {
				/* Enable, and Clock request gpios */
				pins = "gpio189", "gpio198";
				function = "gpio";
			};

			config {
				pins = "gpio189", "gpio198";
				drive-strength = <2>; /* 2 MA */
				bias-disable;
			};
		};

		nfc_enable_suspend: nfc_enable_suspend {
			mux {
				pins = "gpio189", "gpio198";
				function = "gpio";
			};

			config {
				pins = "gpio189", "gpio198";
				drive-strength = <2>; /* 2 MA */
				bias-disable;
			};
		};
	}; //nfc
}; //tlmm
// ASUS_BSP NFC ---

// ASUS_BSP LiJen SX9325 +++
&qupv3_hub_i2c4{
	status = "ok";
	Semtech_sx932x@28 {
	compatible = "Semtech,sx932x";
	qcom,clk-freq-out = <400000>;
	reg = <0x28>;
	interrupt-parent = <&tlmm>;
	interrupts = <177 0>;
	pinctrl-names = "sx932x_active","sx932x_suspend";
	pinctrl-0 = <&sx932x_active>;
	pinctrl-1 = <&sx932x_suspend>;
		
	Semtech,nirq-gpio = <&tlmm 177 0x00>;
	status = "ok";	/**/
	Semtech,reg-num = <45>; /* total registers number to initialize*/
	Semtech,reg-init  = /bits/ 8 < 0x10 0x1C
                                0x11 0x21
                                0x14 0x00
                                0x15 0x00
                                0x20 0x20
                                0x23 0x00
                                0x24 0x47
                                0x26 0x00
                                0x27 0x47
                                0x28 0x39
                                0x29 0x2D
                                0x2A 0x36
                                0x2B 0x07
                                0x2C 0x12
                                0x2D 0x08
                                0x30 0x23
                                0x31 0x08
                                0x32 0x20
                                0x33 0x20
                                0x34 0x0C
                                0x35 0x00
                                0x36 0x8E
                                0x37 0x00
                                0x40 0x00
                                0x41 0x00
                                0x42 0x00
                                0x43 0x00
                                0x44 0x00
                                0x45 0x05
                                0x46 0x00
                                0x47 0x00
                                0x48 0x00
                                0x49 0x00
                                0x4A 0x00
                                0x4B 0x00
                                0x4C 0x00
                                0x50 0x14
                                0x51 0x70
                                0x52 0x20
                                0x02 0x00
                                0x05 0x6F
                                0x06 0x00
                                0x07 0x80
                                0x08 0x01
                                0x03 0x0F>;
	};
};

&tlmm{
	sx932x_active {
		sx932x_active: sx932x_active {
			mux {
				pins = "gpio177";
				function = "gpio";
			};
			config {
				pins = "gpio177";
				bias-pull-up;
				drive-strength = <6>;
			};
		};
	};
	sx932x_suspend {
		sx932x_suspend: sx932x_suspend {
			mux {
				pins = "gpio177";
				function = "gpio";
			};
			config {
				pins = "gpio177";
				bias-disable;
				drive-strength = <2>;
			};
		};
	};
};
